# Cortex_M23 register map
Vendor: Arm Ltd.; Series: ARMv8-M Baseline; File version: 1.0.0
CPU: CM23 r0p0, little endian, MPU, no FPU, 2 interrupt priority bits
Registers are 32-bit, read-only, reset 0x0 unless marked. A register's access mark holds for its fields unless they carry their own. Offsets are from the block's base; [hi:lo] are bit positions; {n}, {i} and the like mark numbered series.

## MPU — Memory Protection Unit (optional): programmable regions with access permissions and memory attributes, checked on every access. ARMv6-M/v7-M (PMSAv7) use RBAR/RASR power-of-two regions; ARMv8-M (PMSAv8) uses RBAR/RLAR base-limit regions with MAIR attributes.
Base 0xE000ED90
Same registers: MPU_NS 0xE002ED90
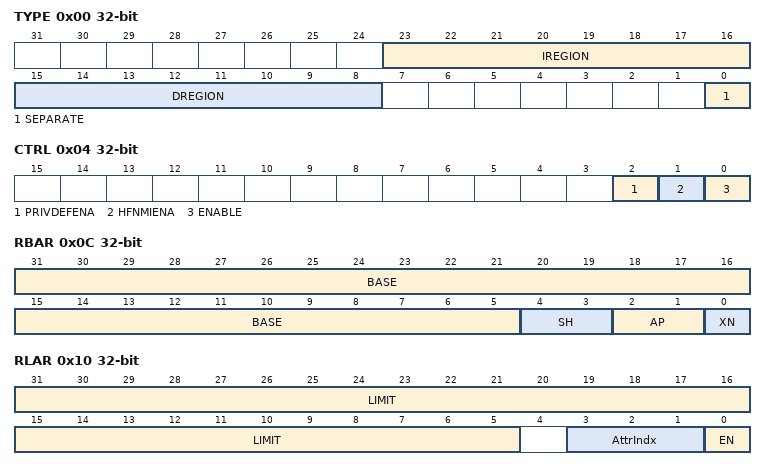
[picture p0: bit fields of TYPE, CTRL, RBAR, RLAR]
0x00 TYPE — MPU Type Register: how many regions the MPU implements (0 = no MPU). Read-only.
  [23:16] IREGION — Number of instruction regions; always 0 (unified).
  [15:8] DREGION — Number of MPU regions implemented (0 = no MPU; Cortex-M cores offer 8 or 16).
  [0] SEPARATE — 0 = unified MPU (instruction and data share the regions). Always 0 on Cortex-M.
0x04 CTRL rw — MPU Control Register: global enable, behaviour during HardFault/NMI, and the privileged default memory map.
  [2] PRIVDEFENA — 1 = privileged accesses to addresses not covered by any enabled region use the default memory map; 0 = they raise a MemManage fault (unprivileged accesses always fault).
  [1] HFNMIENA — 1 = the MPU stays enabled during HardFault, NMI and FAULTMASK handlers; 0 = those handlers use the default memory map (the usual choice).
  [0] ENABLE — MPU enable. When 0 the default memory map applies to all accesses.
0x08 RNR rw — MPU Region Number Register: selects the region that RBAR and RASR/RLAR access.
  [7:0] REGION — Region number selected for RBAR/RASR (RLAR) accesses.
0x0C RBAR rw — MPU Region Base Address Register for the region selected by RNR (ARMv7-M: also selects the region when VALID is set). ARMv8-M: base address, shareability, access permissions and XN.
  [31:5] BASE — Region start address bits [31:5] (32-byte granularity).
  [4:3] SH — Shareability of Normal memory: 0 = non-shareable, 2 = outer shareable, 3 = inner shareable (1 reserved). Ignored for Device memory.
    0=NonShareable; 2=OuterShareable; 3=InnerShareable
  [2:1] AP — Access permissions: 0 = read/write privileged only, 1 = read/write any privilege, 2 = read-only privileged only, 3 = read-only any privilege.
    0=RW_PRIV (Read/write, privileged only); 1=RW_ANY (Read/write, any privilege); 2=RO_PRIV (Read-only, privileged only); 3=RO_ANY (Read-only, any privilege)
  [0] XN — Execute never: 1 = instruction fetches from this region fault.
0x10 RLAR rw — MPU Region Limit Address Register (ARMv8-M PMSAv8): inclusive end address, attribute index into MAIR0/1 and enable of the selected region.
  [31:5] LIMIT — Region end address bits [31:5]; the low five bits are treated as 1, so the region is inclusive up to LIMIT + 31.
  [3:1] AttrIndx — Index (0-7) of the MAIR0/MAIR1 attribute byte that gives the memory type and cacheability of this region.
  [0] EN — Region enable.
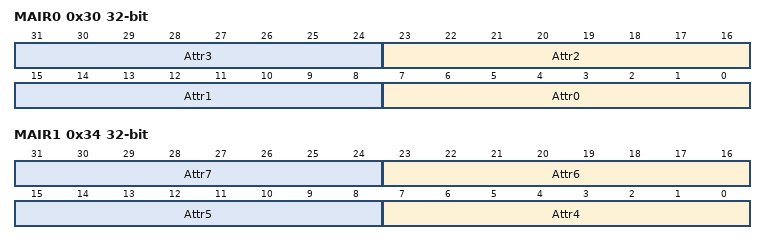
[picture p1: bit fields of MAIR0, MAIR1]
0x30 MAIR0 rw — MPU Memory Attribute Indirection Register 0: memory type/cacheability encodings 0-3 referenced by RLAR.AttrIndx.
  [8n+7:8n] Attr{n} (n=0..3) — Memory attribute encoding {n}, selected by RLAR.AttrIndx: Device memory = 0b0000dd00 (dd: 00 nGnRnE, 01 nGnRE, 10 nGRE, 11 GRE); Normal memory = outer[7:4] inner[3:0] with 0100 non-cacheable, 10RW write-through, 11RW write-back (R = read-allocate, W = write-allocate; 1111 = write-back RWA).
0x34 MAIR1 rw — MPU Memory Attribute Indirection Register 1: memory type/cacheability encodings 4-7 referenced by RLAR.AttrIndx.
  [8n-25:8n-32] Attr{n} (n=4..7) — Memory attribute encoding {n}, selected by RLAR.AttrIndx: Device memory = 0b0000dd00 (dd: 00 nGnRnE, 01 nGnRE, 10 nGRE, 11 GRE); Normal memory = outer[7:4] inner[3:0] with 0100 non-cacheable, 10RW write-through, 11RW write-back (R = read-allocate, W = write-allocate; 1111 = write-back RWA).

## SAU — Security Attribution Unit (ARMv8-M Security Extension): defines which address ranges are Non-secure or Secure Non-secure-callable; everything else is Secure. Also holds the SecureFault status and address registers.
Base 0xE000EDD0
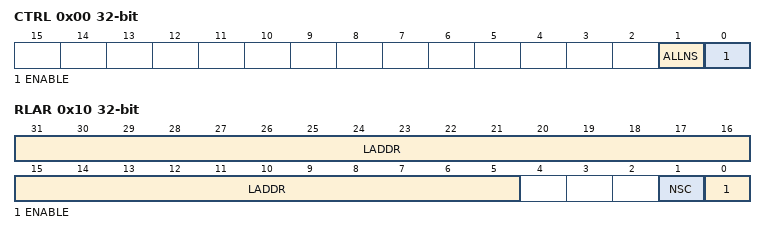
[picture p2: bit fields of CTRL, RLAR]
0x00 CTRL rw — SAU Control Register: enable, and what the memory map looks like while the SAU is disabled.
  [1] ALLNS — All Non-secure: with the SAU disabled, 1 = memory not marked Secure by the IDAU is Non-secure, 0 = all memory is Secure.
  [0] ENABLE — SAU enable. When 0 the whole address space is Secure (ALLNS = 0) or Non-secure (ALLNS = 1), subject to the IDAU.
0x04 TYPE — SAU Type Register: number of SAU regions implemented (0, 4 or 8 on Arm cores). Read-only.
  [7:0] SREGION — Number of SAU regions implemented (0, 4 or 8).
0x08 RNR rw — SAU Region Number Register: selects the region that RBAR and RLAR access.
  [7:0] REGION — Region selected for RBAR/RLAR accesses.
0x0C RBAR rw — SAU Region Base Address Register: start address (32-byte aligned) of the selected region.
  [31:5] BADDR — Region start address bits [31:5] (32-byte granularity).
0x10 RLAR rw — SAU Region Limit Address Register: inclusive end address, Non-secure-callable attribute and enable of the selected region.
  [31:5] LADDR — Region end address bits [31:5]; the low five bits are treated as 1 (inclusive limit).
  [1] NSC — 1 = the region is Secure and Non-secure-callable (holds the SG entry veneers); 0 = the region is Non-secure.
  [0] ENABLE — Region enable.

## DIB — Debug Identification Block (ARMv8-M): software lock, debug authentication status and the SCS CoreSight architecture and type IDs.
Base 0xE000EFB0
Same registers: DIB_NS 0xE002EFB0
0x00 DLAR wo — SCS Software Lock Access Register: write 0xC5ACCE55 to unlock software writes to the SCS debug registers when the software lock is implemented (DLSR.SLI).
  [31:0] KEY — Write 0xC5ACCE55 to unlock software access to the SCS debug registers; any other value locks them.
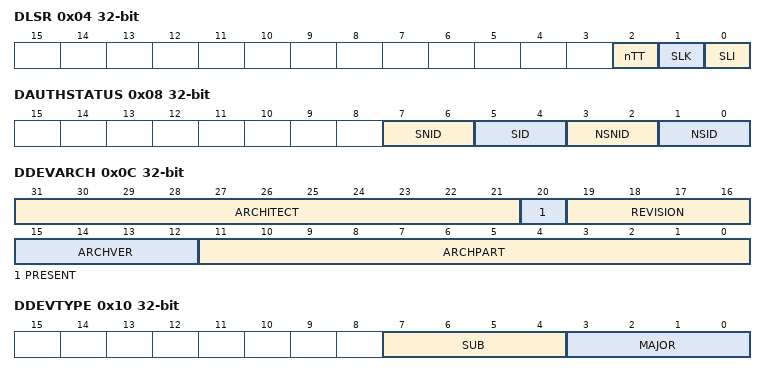
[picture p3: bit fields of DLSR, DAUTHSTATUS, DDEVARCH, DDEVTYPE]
0x04 DLSR — SCS Software Lock Status Register: whether a software lock exists and whether it is currently locked.
  [2] nTT — Not thirty-two bit: 0 = DLAR is a 32-bit register.
  [1] SLK — Software lock status: 1 = locked (software writes to the debug registers are ignored; the debugger is never locked).
  [0] SLI — Software lock implemented.
0x08 DAUTHSTATUS — Debug Authentication Status Register: which kinds of debug (invasive/non-invasive, Secure/Non-secure, unprivileged) are currently enabled.
  [7:6] SNID — Secure non-invasive debug: 0 = not implemented, 2 = disabled, 3 = enabled.
  [5:4] SID — Secure invasive debug: 0 = not implemented, 2 = disabled, 3 = enabled.
  [3:2] NSNID — Non-secure non-invasive debug (trace): 0 = not implemented, 2 = disabled, 3 = enabled.
  [1:0] NSID — Non-secure invasive debug: 0 = not implemented, 2 = disabled, 3 = enabled.
0x0C DDEVARCH — SCS Device Architecture Register: CoreSight ARCHID of the debug architecture (0x2A04 = ARMv8-M debug) and the architect (Arm, 0x23B).
  [31:21] ARCHITECT — JEP106 code of the architect: 0x23B = Arm.
  [20] PRESENT — 1 = DDEVARCH is present and its contents are valid.
  [19:16] REVISION — Architecture revision.
  [15:12] ARCHVER — Architecture version: 2 = ARMv8-M debug architecture.
  [11:0] ARCHPART — Architecture part: 0xA04 = M-profile system control space (with ARCHVER 2 -> ARCHID 0x2A04, ARMv8-M debug).
0x10 DDEVTYPE — SCS Device Type Register: CoreSight major/sub type of the SCS (0x00 = processor system control).
  [7:4] SUB — Sub type: 0 for the SCS.
  [3:0] MAJOR — Major type: 0 = miscellaneous / processor system control.
